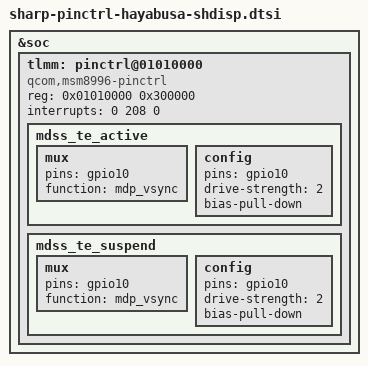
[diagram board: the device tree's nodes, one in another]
/* Copyright (c) 2015, The Linux Foundation. All rights reserved.
 *
 * This program is free software; you can redistribute it and/or modify
 * it under the terms of the GNU General Public License version 2 and
 * only version 2 as published by the Free Software Foundation.
 *
 * This program is distributed in the hope that it will be useful,
 * but WITHOUT ANY WARRANTY; without even the implied warranty of
 * MERCHANTABILITY or FITNESS FOR A PARTICULAR PURPOSE.  See the
 * GNU General Public License for more details.
 */

&soc {
	tlmm: pinctrl@01010000 {
		compatible = "qcom,msm8996-pinctrl";
		reg = <0x01010000 0x300000>;
		interrupts = <0 208 0>;

		mdss_te_active: mdss_te_active {
			mux {
				pins = "gpio10";
				function = "mdp_vsync";
			};
			config {
				pins = "gpio10";
				drive-strength = <2>; /* 2 mA */
				bias-pull-down; /* pull down*/
			};
		};

		mdss_te_suspend: mdss_te_suspend {
			mux {
				pins = "gpio10";
				function = "mdp_vsync";
			};
			config {
				pins = "gpio10";
				drive-strength = <2>; /* 2 mA */
				bias-pull-down; /* pull down */
			};
		};
	};
};

